AUTOSAR XML (schema 4-2-2)
package /ComponentTypes
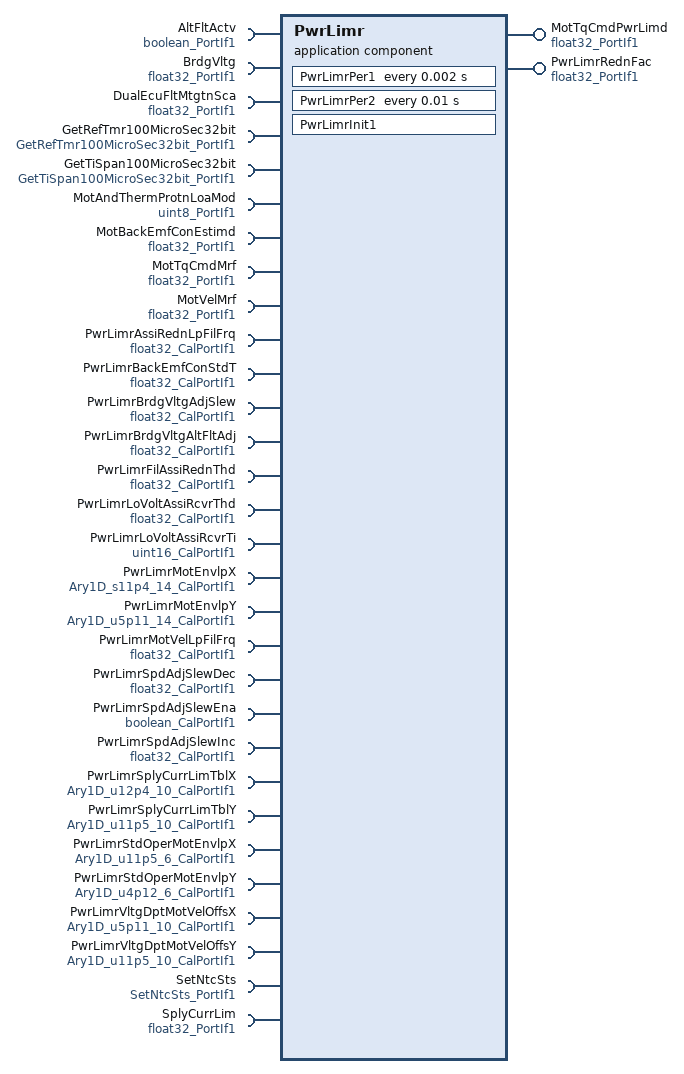
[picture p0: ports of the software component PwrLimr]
  application sw component type PwrLimr
    provide port MotTqCmdPwrLimd: nonqueued-sender-com-spec{data-element=Val, init-value=0}, provided-interface=float32_PortIf1
    provide port PwrLimrRednFac: nonqueued-sender-com-spec{data-element=Val, init-value=0}, provided-interface=float32_PortIf1
    30 x require port:
      AltFltActv: nonqueued-receiver-com-spec{data-element=Logl, filter=data-filter-type=ALWAYS, init-value=0}, required-interface=boolean_PortIf1
      BrdgVltg: nonqueued-receiver-com-spec{data-element=Val, filter=data-filter-type=ALWAYS, init-value=6}, required-interface=float32_PortIf1
      DualEcuFltMtgtnSca: nonqueued-receiver-com-spec{data-element=Val, filter=data-filter-type=ALWAYS, init-value=0.5}, required-interface=float32_PortIf1
      GetRefTmr100MicroSec32bit: client-com-spec=Oper, required-interface=GetRefTmr100MicroSec32bit_PortIf1
      GetTiSpan100MicroSec32bit: client-com-spec=Oper, required-interface=GetTiSpan100MicroSec32bit_PortIf1
      MotAndThermProtnLoaMod: nonqueued-receiver-com-spec{data-element=Val, filter=data-filter-type=ALWAYS, init-value=0}, required-interface=uint8_PortIf1
      MotBackEmfConEstimd: nonqueued-receiver-com-spec{data-element=Val, filter=data-filter-type=ALWAYS, init-value=0.025}, required-interface=float32_PortIf1
      MotTqCmdMrf: nonqueued-receiver-com-spec{data-element=Val, filter=data-filter-type=ALWAYS, init-value=0}, required-interface=float32_PortIf1
      MotVelMrf: nonqueued-receiver-com-spec{data-element=Val, filter=data-filter-type=ALWAYS, init-value=0}, required-interface=float32_PortIf1
      PwrLimrAssiRednLpFilFrq: parameter-require-com-spec{init-value=0.365, parameter=Val}, required-interface=float32_CalPortIf1
      PwrLimrBackEmfConStdT: parameter-require-com-spec{init-value=0.0335999, parameter=Val}, required-interface=float32_CalPortIf1
      PwrLimrBrdgVltgAdjSlew: parameter-require-com-spec{init-value=0.5, parameter=Val}, required-interface=float32_CalPortIf1
      PwrLimrBrdgVltgAltFltAdj: parameter-require-com-spec{init-value=1, parameter=Val}, required-interface=float32_CalPortIf1
      PwrLimrFilAssiRednThd: parameter-require-com-spec{init-value=0.6, parameter=Val}, required-interface=float32_CalPortIf1
      PwrLimrLoVoltAssiRcvrThd: parameter-require-com-spec{init-value=13.5, parameter=Val}, required-interface=float32_CalPortIf1
      PwrLimrLoVoltAssiRcvrTi: parameter-require-com-spec{init-value=2000, parameter=Val}, required-interface=uint16_CalPortIf1
      PwrLimrMotEnvlpX: parameter-require-com-spec{init-value=[-17600, -12800, -10400, -8800, -5657, -4600, -3499, -1731, 0, 1731, 3499, 4600, 5657, 8800], parameter=Ary1D}, required-interface=Ary1D_s11p4_14_CalPortIf1
      PwrLimrMotEnvlpY: parameter-require-com-spec{init-value=[1475, 2867, 3891, 4710, 7168, 8397, 9486, 9486, 9486, 9486, 7277, 5994, 4506, 0], parameter=Ary1D}, required-interface=Ary1D_u5p11_14_CalPortIf1
      PwrLimrMotVelLpFilFrq: parameter-require-com-spec{init-value=100, parameter=Val}, required-interface=float32_CalPortIf1
      PwrLimrSpdAdjSlewDec: parameter-require-com-spec{init-value=3.125, parameter=Val}, required-interface=float32_CalPortIf1
      PwrLimrSpdAdjSlewEna: parameter-require-com-spec{init-value=1, parameter=Logl}, required-interface=boolean_CalPortIf1
      PwrLimrSpdAdjSlewInc: parameter-require-com-spec{init-value=3125, parameter=Val}, required-interface=float32_CalPortIf1
      PwrLimrSplyCurrLimTblX: parameter-require-com-spec{init-value=[320, 480, 640, 800, 960, 1120, 1280, 1440, 1600, 1920], parameter=Ary1D}, required-interface=Ary1D_u12p4_10_CalPortIf1
      PwrLimrSplyCurrLimTblY: parameter-require-com-spec{init-value=[10304, 7874, 5864, 4106, 2848, 1742, 0, 0, 0, 0], parameter=Ary1D}, required-interface=Ary1D_u11p5_10_CalPortIf1
      PwrLimrStdOperMotEnvlpX: parameter-require-com-spec{init-value=[0, 2182, 5717, 7919, 10034, 16320], parameter=Ary1D}, required-interface=Ary1D_u11p5_6_CalPortIf1
      PwrLimrStdOperMotEnvlpY: parameter-require-com-spec{init-value=[18973, 18973, 14553, 11989, 9011, 0], parameter=Ary1D}, required-interface=Ary1D_u4p12_6_CalPortIf1
      PwrLimrVltgDptMotVelOffsX: parameter-require-com-spec{init-value=[17496, 18728, 18928, 19136, 19336, 19544, 20568, 21592, 22208, 25280], parameter=Ary1D}, required-interface=Ary1D_u5p11_10_CalPortIf1
      PwrLimrVltgDptMotVelOffsY: parameter-require-com-spec{init-value=[3395, 2859, 2769, 2680, 2591, 2501, 2054, 1608, 1340, 0], parameter=Ary1D}, required-interface=Ary1D_u11p5_10_CalPortIf1
      SetNtcSts: client-com-spec=Oper, required-interface=SetNtcSts_PortIf1
      SplyCurrLim: nonqueued-receiver-com-spec{data-element=Val, filter=data-filter-type=ALWAYS, init-value=120}, required-interface=float32_PortIf1
    behavior PwrLimr_InternalBehavior
      ar-typed-per-instance-memorys:
        21 x data, all with sw-calibration-access=READ-ONLY:
          BrdgVltgRateLim: type=float32
          dPwrLimrFildMotVel: type=float32
          dPwrLimrLimDif: type=float32
          dPwrLimrMinStdOperLim: type=float32
          dPwrLimrMotEnvlpSpd: type=float32
          dPwrLimrMotTqCmdIvtrLoaSca: type=float32
          dPwrLimrOutpVelOffs: type=float32
          dPwrLimrSpdAdj: type=float32
          dPwrLimrSplyCurrLimOffs: type=float32
          dPwrLimrTLimMaxCurr: type=float32
          dPwrLimrTqEnvlpLim1: type=float32
          dPwrLimrTqEnvlpLim4: type=float32
          dPwrLimrTqLim: type=float32
          dPwrLimrTqLim1: type=float32
          dPwrLimrTqLim4: type=float32
          LimdAssiLoVltgPrev: type=boolean
          MotVelLpFil: type=FilLpRec1
          OutpVelOffsRateLimd: type=float32
          RefTmr: type=uint32
          RefTmrPrev: type=uint32
          TqLimLpFil: type=FilLpRec1
      init event PwrLimr_InitEvent: start-on-event=PwrLimrInit1
      timing event TMT_PwrLimrPer1: start-on-event=PwrLimrPer1, period=0.002
      timing event TMT_PwrLimrPer2: start-on-event=PwrLimrPer2, period=0.01
      explicit-inter-runnable-variables:
        data MinStdOperLim: type=float32, init-value=0
        data MotEnvlpSpd: type=float32, init-value=0
        data TqEnvlpLim1: type=float32, init-value=0
      port-api-options:
        enable-take-address=false, error-handling=NO-TRANSFORMER-ERROR-HANDLING, indirect-api=false, port=DualEcuFltMtgtnSca
        enable-take-address=false, error-handling=NO-TRANSFORMER-ERROR-HANDLING, indirect-api=false, port=MotTqCmdPwrLimd
        enable-take-address=false, error-handling=NO-TRANSFORMER-ERROR-HANDLING, indirect-api=false, port=PwrLimrSplyCurrLimTblX
        enable-take-address=false, error-handling=NO-TRANSFORMER-ERROR-HANDLING, indirect-api=false, port=PwrLimrSplyCurrLimTblY
        enable-take-address=false, error-handling=NO-TRANSFORMER-ERROR-HANDLING, indirect-api=false, port=PwrLimrStdOperMotEnvlpX
        enable-take-address=false, error-handling=NO-TRANSFORMER-ERROR-HANDLING, indirect-api=false, port=PwrLimrStdOperMotEnvlpY
        enable-take-address=false, error-handling=NO-TRANSFORMER-ERROR-HANDLING, indirect-api=false, port=PwrLimrVltgDptMotVelOffsX
        enable-take-address=false, error-handling=NO-TRANSFORMER-ERROR-HANDLING, indirect-api=false, port=SplyCurrLim
      runnable PwrLimrInit1
        sync call SC_GetRefTmr100MicroSec32bit_Oper_1: operation=GetRefTmr100MicroSec32bit.Oper, timeout=0
      runnable PwrLimrPer1
        data-receive-point-by-arguments:
          8 x access:
            REC_AltFltActv_Logl: accessed-variable=AltFltActv.Logl
            REC_BrdgVltg_Val: accessed-variable=BrdgVltg.Val
            REC_DualEcuFltMtgtnSca_Val: accessed-variable=DualEcuFltMtgtnSca.Val
            REC_MotAndThermProtnLoaMod_Val: accessed-variable=MotAndThermProtnLoaMod.Val
            REC_MotBackEmfConEstimd_Val: accessed-variable=MotBackEmfConEstimd.Val
            REC_MotTqCmdMrf_Val: accessed-variable=MotTqCmdMrf.Val
            REC_MotVelMrf_Val: accessed-variable=MotVelMrf.Val
            REC_SplyCurrLim_Val: accessed-variable=SplyCurrLim.Val
        data-send-points:
          access SEND_MotTqCmdPwrLimd_Val: accessed-variable=MotTqCmdPwrLimd.Val
        written-local-variables:
          access WRITE_MinStdOperLim: accessed-variable=MinStdOperLim
          access WRITE_MotEnvlpSpd: accessed-variable=MotEnvlpSpd
          access WRITE_TqEnvlpLim1: accessed-variable=TqEnvlpLim1
      runnable PwrLimrPer2
        data-receive-point-by-arguments:
          access READ_BrdgVltg_Val: accessed-variable=BrdgVltg.Val
          access READ_MotTqCmdMrf_Val: accessed-variable=MotTqCmdMrf.Val
        data-send-points:
          access SEND_PwrLimrRednFac_Val: accessed-variable=PwrLimrRednFac.Val
        read-local-variables:
          access READ_MinStdOperLim: accessed-variable=MinStdOperLim
          access READ_MotEnvlpSpd: accessed-variable=MotEnvlpSpd
          access READ_TqEnvlpLim1: accessed-variable=TqEnvlpLim1
        sync call SC_GetRefTmr100MicroSec32bit_Oper_1: operation=GetRefTmr100MicroSec32bit.Oper, timeout=0
        sync call SC_GetTiSpan100MicroSec32bit_Oper_1: operation=GetTiSpan100MicroSec32bit.Oper, timeout=0
        sync call SC_SetNtcSts_Oper: operation=SetNtcSts.Oper, timeout=0
  swc implementation PwrLimr_Implementation: behavior=PwrLimr_InternalBehavior
    code-descriptors:
      code Default: artifact-descriptors=autosar-engineering-object={short-label=Default, category=SWSRC}
